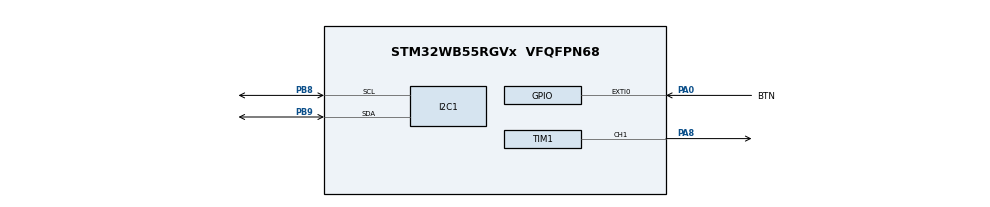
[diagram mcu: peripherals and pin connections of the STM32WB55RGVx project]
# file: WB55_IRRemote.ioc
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I2C1.Timing=0x00B07CB4
Mcu.Family=STM32WB
Mcu.Name=STM32WB55RGVx
Mcu.Package=VFQFPN68
NVIC.EXTI0_IRQn=true\:0\:0\:false\:false\:true\:true\:true\:true
NVIC.PriorityGroup=NVIC_PRIORITYGROUP_4
NVIC.TIM1_UP_TIM16_IRQn=true\:0\:0\:false\:false\:true\:true\:true\:true
PA0.GPIO_Label=BTN
PA0.Signal=GPXTI0
PA8.Signal=S_TIM1_CH1
PB8.Mode=I2C
PB8.Signal=I2C1_SCL
PB9.Mode=I2C
PB9.Signal=I2C1_SDA
ProjectManager.HeapSize=0x200
ProjectManager.StackSize=0x400
ProjectManager.TargetToolchain=STM32CubeIDE
RCC.ADCFreq_Value=128000000
RCC.AHBFreq_Value=32000000
RCC.APB1Freq_Value=32000000
RCC.APB1TimFreq_Value=32000000
RCC.APB2Freq_Value=32000000
RCC.APB2TimFreq_Value=32000000
RCC.APB3Freq_Value=16000000
RCC.CortexFreq_Value=32000000
RCC.HCLKFreq_Value=32000000
RCC.HSE_VALUE=32000000
RCC.HSI48_VALUE=48000000
RCC.HSI_VALUE=16000000
RCC.LSE_VALUE=32768
RCC.MSIClockRange=RCC_MSIRANGE_10
RCC.SMPSCLockSelection=RCC_SMPSCLKSOURCE_HSI
RCC.SMPSCLockSelectionVirtual=RCC_SMPSCLKSOURCE_HSI
RCC.SMPSCLockSelectionVirtualVirtual=RCC_SMPSCLKSOURCE_HSI
RCC.SMPSDivider=1
RCC.SYSCLKFreq_VALUE=32000000
RCC.USBFreq_Value=128000000
RCC.VCOOutputFreq_Value=256000000
SH.S_TIM1_CH1.0=TIM1_CH1,PWM Generation1 CH1
TIM1.Channel-PWM\ Generation1\ CH1=TIM_CHANNEL_1
TIM1.Period=810
TIM1.Pulse-PWM\ Generation1\ CH1=267
VP_MEMORYMAP_VS_MEMORYMAP.Mode=CurAppReg
board=NUCLEO-WB55RG

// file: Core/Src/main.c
/* USER CODE BEGIN Header */
/**
  ******************************************************************************
  * @file           : main.c
  * @brief          : Main program body
  ******************************************************************************
  * @attention
  *
  * Copyright (c) 2025 STMicroelectronics.
  * All rights reserved.
  *
  * This software is licensed under terms that can be found in the LICENSE file
  * in the root directory of this software component.
  * If no LICENSE file comes with this software, it is provided AS-IS.
  *
  ******************************************************************************
  */
/* USER CODE END Header */
#include "main.h"

/* USER CODE BEGIN Includes */

#include "IRInterface/IRInterface.h"

/* USER CODE END Includes */

I2C_HandleTypeDef hi2c1;

TIM_HandleTypeDef htim1;

void SystemClock_Config(void);
void PeriphCommonClock_Config(void);
static void MX_GPIO_Init(void);
static void MX_TIM1_Init(void);
static void MX_I2C1_Init(void);

int main(void)
{

  /* MCU Configuration--------------------------------------------------------*/

  /* Reset of all peripherals, Initializes the Flash interface and the Systick. */
  HAL_Init();

  /* Configure the system clock */
  SystemClock_Config();

  /* Configure the peripherals common clocks */
  PeriphCommonClock_Config();

  /* Initialize all configured peripherals */
  MX_GPIO_Init();
  MX_TIM1_Init();
  MX_I2C1_Init();
  /* USER CODE BEGIN 2 */

  IRInterface_Init(&hi2c1);

  /* USER CODE END 2 */

  /* Infinite loop */
  while (1)
  {

  }
}

void SystemClock_Config(void)
{
  RCC_OscInitTypeDef RCC_OscInitStruct = {0};
  RCC_ClkInitTypeDef RCC_ClkInitStruct = {0};

  /** Configure the main internal regulator output voltage
  */
  __HAL_PWR_VOLTAGESCALING_CONFIG(PWR_REGULATOR_VOLTAGE_SCALE1);

  /** Initializes the RCC Oscillators according to the specified parameters
  * in the RCC_OscInitTypeDef structure.
  */
  RCC_OscInitStruct.OscillatorType = RCC_OSCILLATORTYPE_HSI|RCC_OSCILLATORTYPE_MSI;
  RCC_OscInitStruct.HSIState = RCC_HSI_ON;
  RCC_OscInitStruct.MSIState = RCC_MSI_ON;
  RCC_OscInitStruct.HSICalibrationValue = RCC_HSICALIBRATION_DEFAULT;
  RCC_OscInitStruct.MSICalibrationValue = RCC_MSICALIBRATION_DEFAULT;
  RCC_OscInitStruct.MSIClockRange = RCC_MSIRANGE_10;
  RCC_OscInitStruct.PLL.PLLState = RCC_PLL_NONE;
  if (HAL_RCC_OscConfig(&RCC_OscInitStruct) != HAL_OK)
  {
    Error_Handler();
  }

  /** Configure the SYSCLKSource, HCLK, PCLK1 and PCLK2 clocks dividers
  */
  RCC_ClkInitStruct.ClockType = RCC_CLOCKTYPE_HCLK4|RCC_CLOCKTYPE_HCLK2
                              |RCC_CLOCKTYPE_HCLK|RCC_CLOCKTYPE_SYSCLK
                              |RCC_CLOCKTYPE_PCLK1|RCC_CLOCKTYPE_PCLK2;
  RCC_ClkInitStruct.SYSCLKSource = RCC_SYSCLKSOURCE_MSI;
  RCC_ClkInitStruct.AHBCLKDivider = RCC_SYSCLK_DIV1;
  RCC_ClkInitStruct.APB1CLKDivider = RCC_HCLK_DIV1;
  RCC_ClkInitStruct.APB2CLKDivider = RCC_HCLK_DIV1;
  RCC_ClkInitStruct.AHBCLK2Divider = RCC_SYSCLK_DIV1;
  RCC_ClkInitStruct.AHBCLK4Divider = RCC_SYSCLK_DIV1;

  if (HAL_RCC_ClockConfig(&RCC_ClkInitStruct, FLASH_LATENCY_1) != HAL_OK)
  {
    Error_Handler();
  }
}

void PeriphCommonClock_Config(void)
{
  RCC_PeriphCLKInitTypeDef PeriphClkInitStruct = {0};

  /** Initializes the peripherals clock
  */
  PeriphClkInitStruct.PeriphClockSelection = RCC_PERIPHCLK_SMPS;
  PeriphClkInitStruct.SmpsClockSelection = RCC_SMPSCLKSOURCE_HSI;
  PeriphClkInitStruct.SmpsDivSelection = RCC_SMPSCLKDIV_RANGE0;

  if (HAL_RCCEx_PeriphCLKConfig(&PeriphClkInitStruct) != HAL_OK)
  {
    Error_Handler();
  }
}

static void MX_I2C1_Init(void)
{

  hi2c1.Instance = I2C1;
  hi2c1.Init.Timing = 0x00B07CB4;
  hi2c1.Init.OwnAddress1 = 0;
  hi2c1.Init.AddressingMode = I2C_ADDRESSINGMODE_7BIT;
  hi2c1.Init.DualAddressMode = I2C_DUALADDRESS_DISABLE;
  hi2c1.Init.OwnAddress2 = 0;
  hi2c1.Init.OwnAddress2Masks = I2C_OA2_NOMASK;
  hi2c1.Init.GeneralCallMode = I2C_GENERALCALL_DISABLE;
  hi2c1.Init.NoStretchMode = I2C_NOSTRETCH_DISABLE;
  if (HAL_I2C_Init(&hi2c1) != HAL_OK)
  {
    Error_Handler();
  }

  /** Configure Analogue filter
  */
  if (HAL_I2CEx_ConfigAnalogFilter(&hi2c1, I2C_ANALOGFILTER_ENABLE) != HAL_OK)
  {
    Error_Handler();
  }

  /** Configure Digital filter
  */
  if (HAL_I2CEx_ConfigDigitalFilter(&hi2c1, 0) != HAL_OK)
  {
    Error_Handler();
  }

}

static void MX_TIM1_Init(void)
{

  TIM_MasterConfigTypeDef sMasterConfig = {0};
  TIM_OC_InitTypeDef sConfigOC = {0};
  TIM_BreakDeadTimeConfigTypeDef sBreakDeadTimeConfig = {0};

  htim1.Instance = TIM1;
  htim1.Init.Prescaler = 0;
  htim1.Init.CounterMode = TIM_COUNTERMODE_UP;
  htim1.Init.Period = 810;
  htim1.Init.ClockDivision = TIM_CLOCKDIVISION_DIV1;
  htim1.Init.RepetitionCounter = 0;
  htim1.Init.AutoReloadPreload = TIM_AUTORELOAD_PRELOAD_DISABLE;
  if (HAL_TIM_PWM_Init(&htim1) != HAL_OK)
  {
    Error_Handler();
  }
  sMasterConfig.MasterOutputTrigger = TIM_TRGO_RESET;
  sMasterConfig.MasterOutputTrigger2 = TIM_TRGO2_RESET;
  sMasterConfig.MasterSlaveMode = TIM_MASTERSLAVEMODE_DISABLE;
  if (HAL_TIMEx_MasterConfigSynchronization(&htim1, &sMasterConfig) != HAL_OK)
  {
    Error_Handler();
  }
  sConfigOC.OCMode = TIM_OCMODE_PWM1;
  sConfigOC.Pulse = 267;
  sConfigOC.OCPolarity = TIM_OCPOLARITY_HIGH;
  sConfigOC.OCNPolarity = TIM_OCNPOLARITY_HIGH;
  sConfigOC.OCFastMode = TIM_OCFAST_DISABLE;
  sConfigOC.OCIdleState = TIM_OCIDLESTATE_RESET;
  sConfigOC.OCNIdleState = TIM_OCNIDLESTATE_RESET;
  if (HAL_TIM_PWM_ConfigChannel(&htim1, &sConfigOC, TIM_CHANNEL_1) != HAL_OK)
  {
    Error_Handler();
  }
  sBreakDeadTimeConfig.OffStateRunMode = TIM_OSSR_DISABLE;
  sBreakDeadTimeConfig.OffStateIDLEMode = TIM_OSSI_DISABLE;
  sBreakDeadTimeConfig.LockLevel = TIM_LOCKLEVEL_OFF;
  sBreakDeadTimeConfig.DeadTime = 0;
  sBreakDeadTimeConfig.BreakState = TIM_BREAK_DISABLE;
  sBreakDeadTimeConfig.BreakPolarity = TIM_BREAKPOLARITY_HIGH;
  sBreakDeadTimeConfig.BreakFilter = 0;
  sBreakDeadTimeConfig.BreakAFMode = TIM_BREAK_AFMODE_INPUT;
  sBreakDeadTimeConfig.Break2State = TIM_BREAK2_DISABLE;
  sBreakDeadTimeConfig.Break2Polarity = TIM_BREAK2POLARITY_HIGH;
  sBreakDeadTimeConfig.Break2Filter = 0;
  sBreakDeadTimeConfig.Break2AFMode = TIM_BREAK_AFMODE_INPUT;
  sBreakDeadTimeConfig.AutomaticOutput = TIM_AUTOMATICOUTPUT_DISABLE;
  if (HAL_TIMEx_ConfigBreakDeadTime(&htim1, &sBreakDeadTimeConfig) != HAL_OK)
  {
    Error_Handler();
  }
  HAL_TIM_MspPostInit(&htim1);

}

static void MX_GPIO_Init(void)
{
  GPIO_InitTypeDef GPIO_InitStruct = {0};

  /* GPIO Ports Clock Enable */
  __HAL_RCC_GPIOB_CLK_ENABLE();
  __HAL_RCC_GPIOA_CLK_ENABLE();

  /*Configure GPIO pin : BTN_Pin */
  GPIO_InitStruct.Pin = BTN_Pin;
  GPIO_InitStruct.Mode = GPIO_MODE_IT_RISING;
  GPIO_InitStruct.Pull = GPIO_NOPULL;
  HAL_GPIO_Init(BTN_GPIO_Port, &GPIO_InitStruct);

  /* EXTI interrupt init*/
  HAL_NVIC_SetPriority(EXTI0_IRQn, 0, 0);
  HAL_NVIC_EnableIRQ(EXTI0_IRQn);

}

void Error_Handler(void)
{
  __disable_irq();
  while (1)
  {
  }
}
